# DSPIC33FJ128MC710A register map
Vendor: Microchip
Registers are 16-bit, read-write, reset 0x0 unless marked. A register's access mark holds for its fields unless they carry their own. Addresses are absolute, and some are shared; only a register's first bit layout is shown; [hi:lo] are bit positions; {n}, {i} and the like mark numbered series; 'fields as' and 'values as' point back to an identical list.

## SFR
{0x0+2i} WREG{i} (i=0..14)
0x1E WREG15 reset 0x800
0x20 SPLIM
0x22 ACCAL reset not defined — (power-on value xxxxxxxxxxxxxxxx)
0x24 ACCAH reset not defined — (power-on value xxxxxxxxxxxxxxxx)
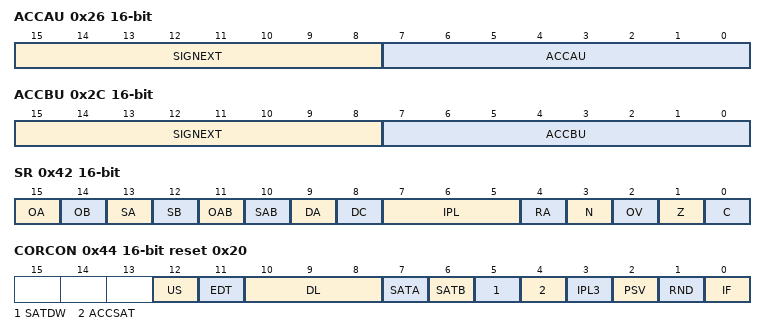
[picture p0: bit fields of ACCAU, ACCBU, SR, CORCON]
0x26 ACCAU reset not defined — (power-on value 00000000xxxxxxxx)
  [15:8] SIGNEXT ro, [7:0] ACCAU
0x28 ACCBL reset not defined — (power-on value xxxxxxxxxxxxxxxx)
0x2A ACCBH reset not defined — (power-on value xxxxxxxxxxxxxxxx)
0x2C ACCBU reset not defined — (power-on value 00000000xxxxxxxx)
  [15:8] SIGNEXT ro, [7:0] ACCBU
0x2E PCL ro
0x30 PCH ro
  [7:0] PCH
0x32 TBLPAG
  [7:0] TBLPAG
0x34 PSVPAG
  [7:0] PSVPAG
0x36 RCOUNT reset not defined — (power-on value --xxxxxxxxxxxxxx)
  [13:0] RCOUNT
0x38 DCOUNT reset not defined — (power-on value --xxxxxxxxxxxxxx)
  [13:0] DCOUNT
0x3A DOSTARTL reset not defined — (power-on value xxxxxxxxxxxxxxx0)
0x3C DOSTARTH reset not defined — (power-on value ----------xxxxxx)
  [5:0] DOSTARTH
0x3E DOENDL reset not defined — (power-on value xxxxxxxxxxxxxxx0)
0x40 DOENDH reset not defined — (power-on value ----------xxxxxx)
  [5:0] DOENDH
0x42 SR
  [15] OA ro
  [14] OB ro
  [13] SA — (can only be cleared)
  [12] SB — (can only be cleared)
  [11] OAB ro
  [10] SAB — (can only be cleared)
  [9] DA ro
  [8] DC
  [7:5] IPL
  [4] RA ro
  [3] N
  [2] OV
  [1] Z
  [0] C
0x44 CORCON reset 0x20
  [12] US
  [11] EDT wo
  [10:8] DL ro
  [7] SATA
  [6] SATB
  [5] SATDW
  [4] ACCSAT
  [3] IPL3 — (can only be cleared)
  [2] PSV
  [1] RND
  [0] IF
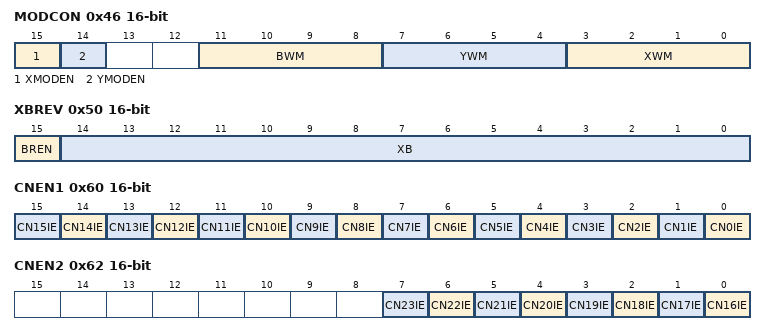
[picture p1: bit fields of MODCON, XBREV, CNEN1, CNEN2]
0x46 MODCON
  [15] XMODEN, [14] YMODEN, [11:8] BWM, [7:4] YWM, [3:0] XWM
0x48 XMODSRT reset not defined — (power-on value xxxxxxxxxxxxxxx0)
  [15:0] XS
0x4A XMODEND reset not defined — (power-on value xxxxxxxxxxxxxxx1)
  [15:0] XE
0x4C YMODSRT reset not defined — (power-on value xxxxxxxxxxxxxxx0)
  [15:0] YS
0x4E YMODEND reset not defined — (power-on value xxxxxxxxxxxxxxx1)
  [15:0] YE
0x50 XBREV reset not defined — (power-on value 0xxxxxxxxxxxxxxx)
  [15] BREN, [14:0] XB
0x52 DISICNT reset not defined — (power-on value --xxxxxxxxxxxxxx)
  [13:0] DISICNT
0x60 CNEN1
  [n] CN{n}IE (n=0..15)
0x62 CNEN2
  [n-16] CN{n}IE (n=16..23)
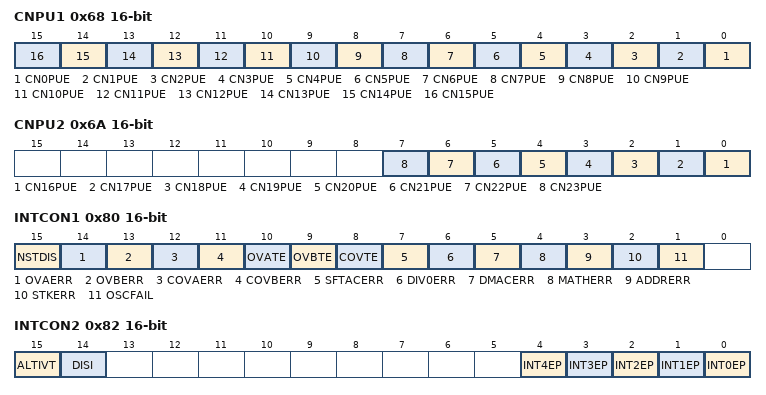
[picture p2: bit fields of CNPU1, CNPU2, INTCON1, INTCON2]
0x68 CNPU1
  [n] CN{n}PUE (n=0..15)
0x6A CNPU2
  [n-16] CN{n}PUE (n=16..23)
0x80 INTCON1
  [15] NSTDIS, [14] OVAERR ro, [13] OVBERR ro, [12] COVAERR ro, [11] COVBERR ro, [10] OVATE, [9] OVBTE, [8] COVTE, [7] SFTACERR ro, [6] DIV0ERR ro, [5] DMACERR, [4] MATHERR, [3] ADDRERR, [2] STKERR, [1] OSCFAIL
0x82 INTCON2
  [15] ALTIVT, [14] DISI ro, [n] INT{n}EP (n=0..4)
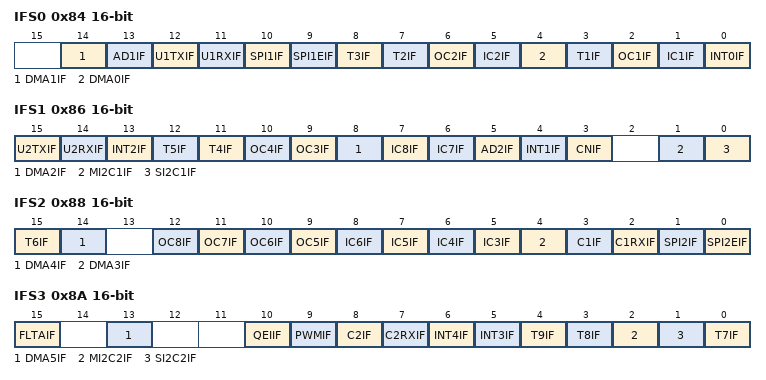
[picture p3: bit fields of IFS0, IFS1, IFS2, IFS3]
0x84 IFS0
  [14] DMA1IF, [13] AD1IF, [12] U1TXIF, [11] U1RXIF, [10] SPI1IF, [9] SPI1EIF, [8] T3IF, [7] T2IF, [6] OC2IF, [5] IC2IF, [4] DMA0IF, [3] T1IF, [2] OC1IF, [1] IC1IF, [0] INT0IF
0x86 IFS1
  [15] U2TXIF, [14] U2RXIF, [13] INT2IF, [12] T5IF, [11] T4IF, [10] OC4IF, [9] OC3IF, [8] DMA2IF, [7] IC8IF, [6] IC7IF, [5] AD2IF, [4] INT1IF, [3] CNIF, [1] MI2C1IF, [0] SI2C1IF
0x88 IFS2
  [15] T6IF, [14] DMA4IF, [n+4] OC{n}IF (n=5..8), [n+2] IC{n}IF (n=3..6), [4] DMA3IF, [3] C1IF, [2] C1RXIF, [1] SPI2IF, [0] SPI2EIF
0x8A IFS3
  [15] FLTAIF, [13] DMA5IF, [10] QEIIF, [9] PWMIF, [8] C2IF, [7] C2RXIF, [6] INT4IF, [5] INT3IF, [4] T9IF, [3] T8IF, [2] MI2C2IF, [1] SI2C2IF, [0] T7IF
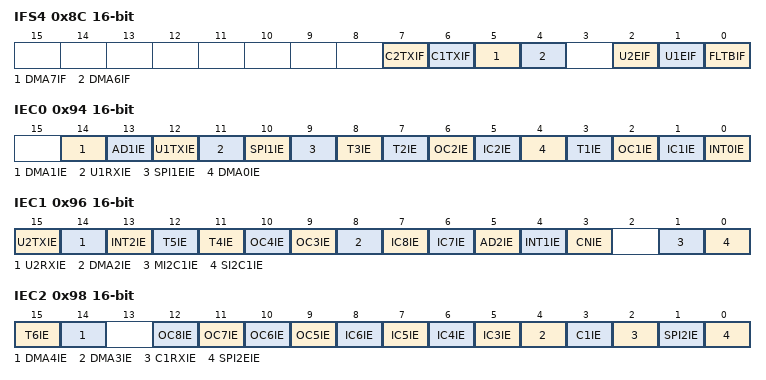
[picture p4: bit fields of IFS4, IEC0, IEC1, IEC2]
0x8C IFS4
  [7] C2TXIF, [6] C1TXIF, [5] DMA7IF, [4] DMA6IF, [2] U2EIF, [1] U1EIF, [0] FLTBIF
0x94 IEC0
  [14] DMA1IE, [13] AD1IE, [12] U1TXIE, [11] U1RXIE, [10] SPI1IE, [9] SPI1EIE, [8] T3IE, [7] T2IE, [6] OC2IE, [5] IC2IE, [4] DMA0IE, [3] T1IE, [2] OC1IE, [1] IC1IE, [0] INT0IE
0x96 IEC1
  [15] U2TXIE, [14] U2RXIE, [13] INT2IE, [12] T5IE, [11] T4IE, [10] OC4IE, [9] OC3IE, [8] DMA2IE, [7] IC8IE, [6] IC7IE, [5] AD2IE, [4] INT1IE, [3] CNIE, [1] MI2C1IE, [0] SI2C1IE
0x98 IEC2
  [15] T6IE, [14] DMA4IE, [n+4] OC{n}IE (n=5..8), [n+2] IC{n}IE (n=3..6), [4] DMA3IE, [3] C1IE, [2] C1RXIE, [1] SPI2IE, [0] SPI2EIE
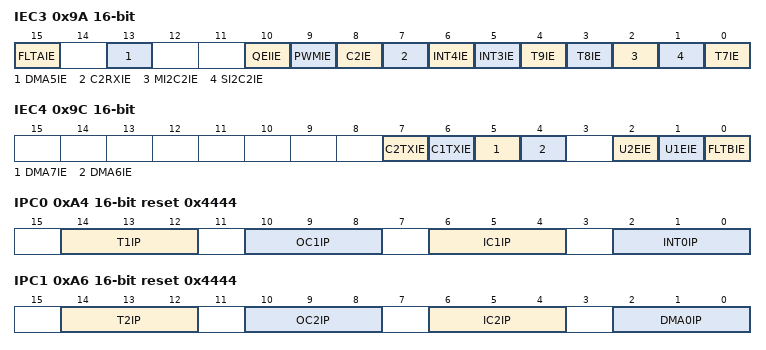
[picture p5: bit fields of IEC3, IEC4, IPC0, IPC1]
0x9A IEC3
  [15] FLTAIE, [13] DMA5IE, [10] QEIIE, [9] PWMIE, [8] C2IE, [7] C2RXIE, [6] INT4IE, [5] INT3IE, [4] T9IE, [3] T8IE, [2] MI2C2IE, [1] SI2C2IE, [0] T7IE
0x9C IEC4
  [7] C2TXIE, [6] C1TXIE, [5] DMA7IE, [4] DMA6IE, [2] U2EIE, [1] U1EIE, [0] FLTBIE
0xA4 IPC0 reset 0x4444
  [14:12] T1IP, [10:8] OC1IP, [6:4] IC1IP, [2:0] INT0IP
0xA6 IPC1 reset 0x4444
  [14:12] T2IP, [10:8] OC2IP, [6:4] IC2IP, [2:0] DMA0IP
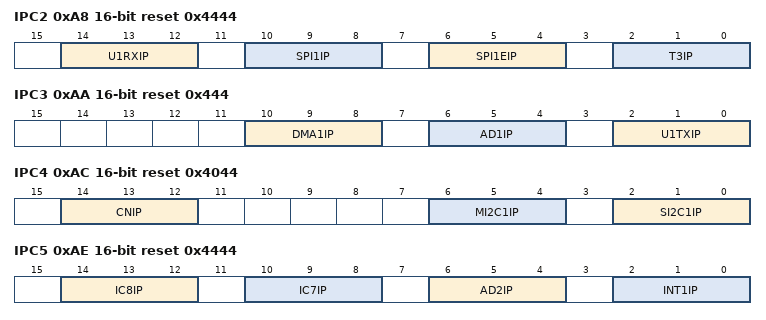
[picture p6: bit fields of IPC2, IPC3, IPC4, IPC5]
0xA8 IPC2 reset 0x4444
  [14:12] U1RXIP, [10:8] SPI1IP, [6:4] SPI1EIP, [2:0] T3IP
0xAA IPC3 reset 0x444
  [10:8] DMA1IP, [6:4] AD1IP, [2:0] U1TXIP
0xAC IPC4 reset 0x4044
  [14:12] CNIP, [6:4] MI2C1IP, [2:0] SI2C1IP
0xAE IPC5 reset 0x4444
  [14:12] IC8IP, [10:8] IC7IP, [6:4] AD2IP, [2:0] INT1IP
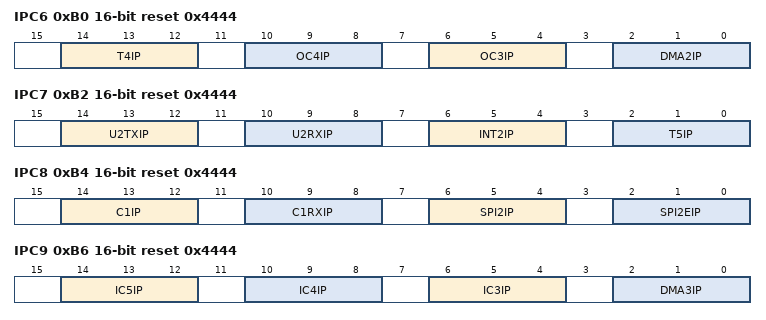
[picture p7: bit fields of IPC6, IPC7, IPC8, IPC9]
0xB0 IPC6 reset 0x4444
  [14:12] T4IP, [10:8] OC4IP, [6:4] OC3IP, [2:0] DMA2IP
0xB2 IPC7 reset 0x4444
  [14:12] U2TXIP, [10:8] U2RXIP, [6:4] INT2IP, [2:0] T5IP
0xB4 IPC8 reset 0x4444
  [14:12] C1IP, [10:8] C1RXIP, [6:4] SPI2IP, [2:0] SPI2EIP
0xB6 IPC9 reset 0x4444
  [14:12] IC5IP, [10:8] IC4IP, [6:4] IC3IP, [2:0] DMA3IP
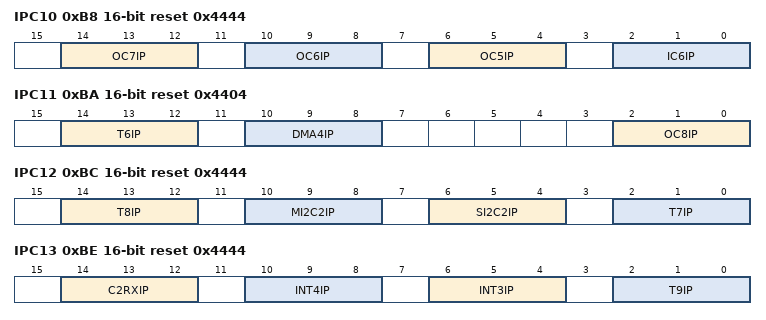
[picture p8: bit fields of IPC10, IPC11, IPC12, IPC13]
0xB8 IPC10 reset 0x4444
  [14:12] OC7IP, [10:8] OC6IP, [6:4] OC5IP, [2:0] IC6IP
0xBA IPC11 reset 0x4404
  [14:12] T6IP, [10:8] DMA4IP, [2:0] OC8IP
0xBC IPC12 reset 0x4444
  [14:12] T8IP, [10:8] MI2C2IP, [6:4] SI2C2IP, [2:0] T7IP
0xBE IPC13 reset 0x4444
  [14:12] C2RXIP, [10:8] INT4IP, [6:4] INT3IP, [2:0] T9IP
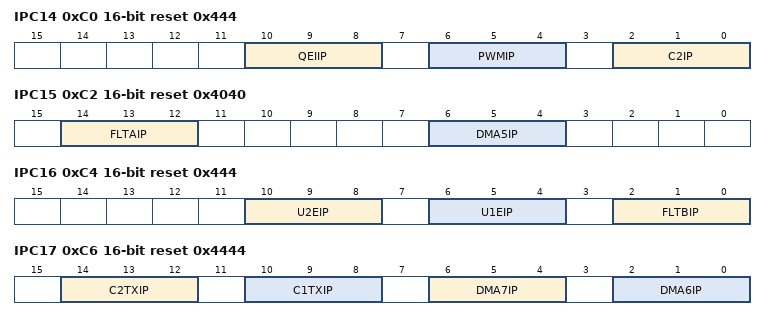
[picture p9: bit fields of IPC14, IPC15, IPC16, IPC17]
0xC0 IPC14 reset 0x444
  [10:8] QEIIP, [6:4] PWMIP, [2:0] C2IP
0xC2 IPC15 reset 0x4040
  [14:12] FLTAIP, [6:4] DMA5IP
0xC4 IPC16 reset 0x444
  [10:8] U2EIP, [6:4] U1EIP, [2:0] FLTBIP
0xC6 IPC17 reset 0x4444
  [14:12] C2TXIP, [10:8] C1TXIP, [6:4] DMA7IP, [2:0] DMA6IP
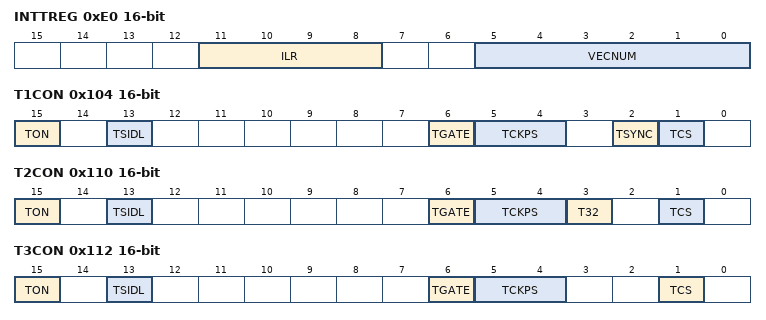
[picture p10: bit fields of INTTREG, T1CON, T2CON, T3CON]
0xE0 INTTREG ro
  [11:8] ILR, [5:0] VECNUM
0x100 TMR1 reset not defined — (power-on value xxxxxxxxxxxxxxxx)
0x102 PR1 reset 0xFFFF
0x104 T1CON
  [15] TON, [13] TSIDL, [6] TGATE, [5:4] TCKPS, [2] TSYNC, [1] TCS
0x106 TMR2 reset not defined — (power-on value xxxxxxxxxxxxxxxx)
0x108 TMR3HLD reset not defined — (power-on value xxxxxxxxxxxxxxxx)
0x10A TMR3 reset not defined — (power-on value xxxxxxxxxxxxxxxx)
0x10C PR2 reset 0xFFFF
0x10E PR3 reset 0xFFFF
0x110 T2CON
  [15] TON, [13] TSIDL, [6] TGATE, [5:4] TCKPS, [3] T32, [1] TCS
0x112 T3CON
  [15] TON, [13] TSIDL, [6] TGATE, [5:4] TCKPS, [1] TCS
0x114 TMR4 reset not defined — (power-on value xxxxxxxxxxxxxxxx)
0x116 TMR5HLD reset not defined — (power-on value xxxxxxxxxxxxxxxx)
0x118 TMR5 reset not defined — (power-on value xxxxxxxxxxxxxxxx)
0x11A PR4 reset 0xFFFF
0x11C PR5 reset 0xFFFF
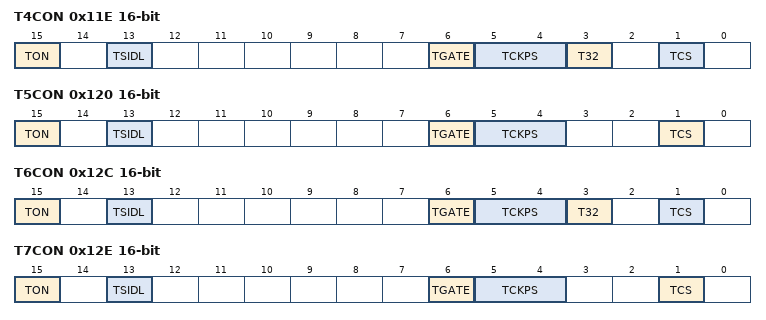
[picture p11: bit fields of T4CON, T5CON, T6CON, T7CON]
0x11E T4CON
  [15] TON, [13] TSIDL, [6] TGATE, [5:4] TCKPS, [3] T32, [1] TCS
0x120 T5CON
  [15] TON, [13] TSIDL, [6] TGATE, [5:4] TCKPS, [1] TCS
0x122 TMR6 reset not defined — (power-on value xxxxxxxxxxxxxxxx)
0x124 TMR7HLD reset not defined — (power-on value xxxxxxxxxxxxxxxx)
0x126 TMR7 reset not defined — (power-on value xxxxxxxxxxxxxxxx)
0x128 PR6 reset 0xFFFF
0x12A PR7 reset 0xFFFF
0x12C T6CON
  [15] TON, [13] TSIDL, [6] TGATE, [5:4] TCKPS, [3] T32, [1] TCS
0x12E T7CON
  [15] TON, [13] TSIDL, [6] TGATE, [5:4] TCKPS, [1] TCS
0x130 TMR8 reset not defined — (power-on value xxxxxxxxxxxxxxxx)
0x132 TMR9HLD reset not defined — (power-on value xxxxxxxxxxxxxxxx)
0x134 TMR9 reset not defined — (power-on value xxxxxxxxxxxxxxxx)
0x136 PR8 reset 0xFFFF
0x138 PR9 reset 0xFFFF
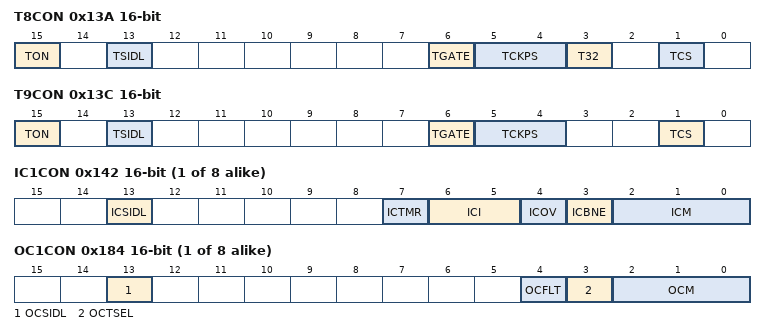
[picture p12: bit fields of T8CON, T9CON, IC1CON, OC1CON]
0x13A T8CON
  [15] TON, [13] TSIDL, [6] TGATE, [5:4] TCKPS, [3] T32, [1] TCS
0x13C T9CON
  [15] TON, [13] TSIDL, [6] TGATE, [5:4] TCKPS, [1] TCS
{0x13C+4i} IC{i}BUF ro reset not defined (i=1..8) — (power-on value xxxxxxxxxxxxxxxx)
{0x13E+4i} IC{i}CON (i=1..8)
  [13] ICSIDL, [7] ICTMR, [6:5] ICI, [4] ICOV ro, [3] ICBNE ro, [2:0] ICM
{0x17A+6i} OC{i}RS reset not defined (i=1..5) — (power-on value xxxxxxxxxxxxxxxx)
{0x17C+6i} OC{i}R reset not defined (i=1..5) — (power-on value xxxxxxxxxxxxxxxx)
{0x17E+6i} OC{i}CON (i=1..8)
  [13] OCSIDL, [4] OCFLT ro, [3] OCTSEL, [2:0] OCM
{0x17A+6i} OC{i}RS (i=6..8)
{0x17C+6i} OC{i}R (i=6..8)
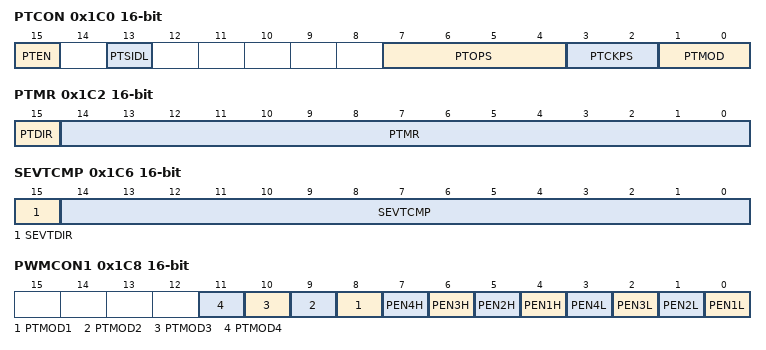
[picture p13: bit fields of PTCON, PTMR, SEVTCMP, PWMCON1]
0x1C0 PTCON
  [15] PTEN, [13] PTSIDL, [7:4] PTOPS, [3:2] PTCKPS, [1:0] PTMOD
0x1C2 PTMR
  [15] PTDIR ro, [14:0] PTMR
0x1C4 PTPER reset 0x7FFF
  [14:0] PTPER
0x1C6 SEVTCMP
  [15] SEVTDIR, [14:0] SEVTCMP
0x1C8 PWMCON1 reset not defined — (power-on value ----0000qqqqqqqq)
  [n+7] PTMOD{n} (n=1..4), [n+3] PEN{n}H (n=1..4), [n-1] PEN{n}L (n=1..4)
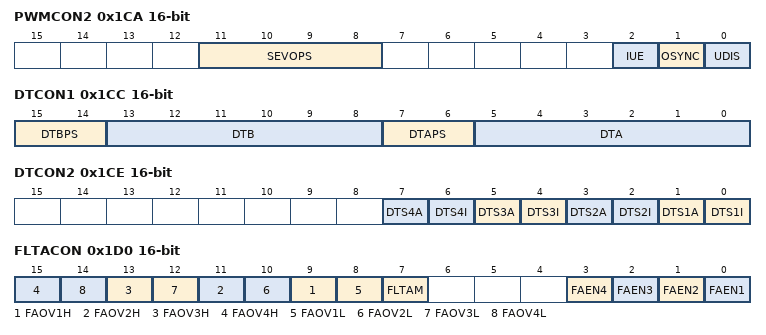
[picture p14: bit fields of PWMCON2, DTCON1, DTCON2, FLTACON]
0x1CA PWMCON2
  [11:8] SEVOPS, [2] IUE, [1] OSYNC, [0] UDIS
0x1CC DTCON1
  [15:14] DTBPS, [13:8] DTB, [7:6] DTAPS, [5:0] DTA
0x1CE DTCON2
  [2n-1] DTS{n}A (n=1..4), [2n-2] DTS{n}I (n=1..4)
0x1D0 FLTACON
  [2n+7] FAOV{n}H (n=1..4), [2n+6] FAOV{n}L (n=1..4), [7] FLTAM, [n-1] FAEN{n} (n=1..4)
0x1D2 FLTBCON
  [2n+7] FBOV{n}H (n=1..4), [2n+6] FBOV{n}L (n=1..4), [7] FLTBM, [n-1] FBEN{n} (n=1..4)
0x1D4 OVDCON reset 0xFF00
  [2n+7] POVD{n}H (n=1..4), [2n+6] POVD{n}L (n=1..4), [2n-1] POUT{n}H (n=1..4), [2n-2] POUT{n}L (n=1..4)
{0x1D4+2i} PDC{i} (i=1..4)
0x1E0 QEICON
  [15] CNTERR, [13] QEISIDL, [12] INDX ro, [11] UPDN, [10] QEIM2, [9] QEIM1, [8] QEIM0, [7] SWPAB, [6] PCDOUT, [5] TQGATE, [4] TQCKPS1, [3] TQCKPS0, [2] POSRES, [1] TQCS, [0] UPDN_SRC
0x1E2 DFLTCON
  [10] IMV1, [9] IMV0, [8] CEID, [7] QEOUT, [6] QECK2, [5] QECK1, [4] QECK0
0x1E4 POSCNT
0x1E6 MAXCNT reset 0xFFFF
0x200 I2C1RCV ro
  [7:0] I2C1RCV
0x202 I2C1TRN wo reset 0xFF
  [7:0] I2C1TRN
0x204 I2C1BRG
  [8:0] I2C1BRG
0x206 I2C1CON reset 0x1000
  [15] I2CEN, [13] I2CSIDL, [12] SCLREL, [11] IPMIEN, [10] A10M, [9] DISSLW, [8] SMEN, [7] GCEN, [6] STREN, [5] ACKDT, [4] ACKEN, [3] RCEN, [2] PEN, [1] RSEN, [0] SEN
0x208 I2C1STAT
  [15] ACKSTAT ro
  [14] TRSTAT ro
  [10] BCL — (can only be cleared)
  [9] GCSTAT ro
  [8] ADD10 ro
  [7] IWCOL — (can only be cleared)
  [6] I2COV — (can only be cleared)
  [5] D_A ro
  [4] P — (can only be cleared)
  [3] S — (can only be cleared)
  [2] R_W ro
  [1] RBF ro
  [0] TBF ro
0x20A I2C1ADD
  [9:0] I2C1ADD
0x20C I2C1MSK
  [9:0] AMSK
0x210 I2C2RCV ro
  [7:0] I2C2RCV
0x212 I2C2TRN wo reset 0xFF
  [7:0] I2C2TRN
0x214 I2C2BRG
  [8:0] I2C2BRG
0x216 I2C2CON reset 0x1000
  fields as I2C1CON
0x218 I2C2STAT
  fields as I2C1STAT
0x21A I2C2ADD
  [9:0] I2C2ADD
0x21C I2C2MSK
  [9:0] AMSK
0x220 U1MODE
  [15] UARTEN, [13] USIDL, [12] IREN, [11] RTSMD, [9:8] UEN, [7] WAKE, [6] LPBACK, [5] ABAUD, [4] URXINV, [3] BRGH, [2:1] PDSEL, [0] STSEL
0x222 U1STA reset 0x110
  [15] UTXISEL1
  [14] UTXINV
  [13] UTXISEL0
  [11] UTXBRK
  [10] UTXEN
  [9] UTXBF ro
  [8] TRMT ro
  [7:6] URXISEL
  [5] ADDEN
  [4] RIDLE ro
  [3] PERR ro
  [2] FERR ro
  [1] OERR — (can only be cleared)
  [0] URXDA ro
0x224 U1TXREG wo reset not defined — (power-on value -------xxxxxxxxx)
  [8:0] U1TXREG
0x226 U1RXREG ro
  [8:0] U1RXREG
0x228 U1BRG
  [15:0] BRG
0x230 U2MODE
  fields as U1MODE
0x232 U2STA reset 0x110
  fields as U1STA
0x234 U2TXREG wo reset not defined — (power-on value -------xxxxxxxxx)
  [8:0] U2TXREG
0x236 U2RXREG ro
  [8:0] U2RXREG
0x238 U2BRG
  [15:0] BRG
0x240 SPI1STAT
  [15] SPIEN
  [13] SPISIDL
  [6] SPIROV — (can only be cleared)
  [1] SPITBF
  [0] SPIRBF
0x242 SPI1CON1
  [12] DISSCK, [11] DISSDO, [10] MODE16, [9] SMP, [8] CKE, [7] SSEN, [6] CKP, [5] MSTEN, [4:2] SPRE, [1:0] PPRE
0x244 SPI1CON2
  [15] FRMEN, [14] SPIFSD, [13] FRMPOL, [1] FRMDLY
0x248 SPI1BUF
0x260 SPI2STAT
  fields as SPI1STAT
0x262 SPI2CON1
  fields as SPI1CON1
0x264 SPI2CON2
  [15] FRMEN, [14] SPIFSD, [13] FRMPOL, [1] FRMDLY
0x268 SPI2BUF
0x2C0 TRISA reset 0xC6FF
  [15] TRISA15, [14] TRISA14, [10] TRISA10, [9] TRISA9, [n] TRISA{n} (n=0..7)
0x2C2 PORTA reset not defined — (power-on value xx---xx-xxxxxxxx)
  [15] RA15, [14] RA14, [10] RA10, [9] RA9, [n] RA{n} (n=0..7)
0x2C4 LATA
  [15] LATA15, [14] LATA14, [10] LATA10, [9] LATA9, [n] LATA{n} (n=0..7)
0x2C6 TRISB reset 0xFFFF
  [n] TRISB{n} (n=0..15)
0x2C8 PORTB reset not defined — (power-on value xxxxxxxxxxxxxxxx)
  [n] RB{n} (n=0..15)
0x2CA LATB
  [n] LATB{n} (n=0..15)
0x2CC TRISC reset 0xF01E
  [n] TRISC{n} (n=12..15), [n] TRISC{n} (n=1..4)
0x2CE PORTC reset not defined — (power-on value xxxx-------xxxx-)
  [n] RC{n} (n=12..15), [n] RC{n} (n=1..4)
0x2D0 LATC
  [n] LATC{n} (n=12..15), [n] LATC{n} (n=1..4)
0x2D2 TRISD reset 0xFFFF
  [n] TRISD{n} (n=0..15)
0x2D4 PORTD reset not defined — (power-on value xxxxxxxxxxxxxxxx)
  [n] RD{n} (n=0..15)
0x2D6 LATD
  [n] LATD{n} (n=0..15)
0x2D8 TRISE reset 0x3FF
  [n] TRISE{n} (n=0..9)
0x2DA PORTE reset not defined — (power-on value ------xxxxxxxxxx)
  [n] RE{n} (n=0..9)
0x2DC LATE
  [n] LATE{n} (n=0..9)
0x2DE TRISF reset 0x31FF
  [13] TRISF13, [12] TRISF12, [n] TRISF{n} (n=0..8)
0x2E0 PORTF reset not defined — (power-on value --xx---xxxxxxxxx)
  [13] RF13, [12] RF12, [n] RF{n} (n=0..8)
0x2E2 LATF
  [13] LATF13, [12] LATF12, [n] LATF{n} (n=0..8)
0x2E4 TRISG reset 0xF3CF
  [n] TRISG{n} (n=12..15), [n] TRISG{n} (n=6..9), [n] TRISG{n} (n=0..3)
0x2E6 PORTG reset not defined — (power-on value xxxx--xxxx--xxxx)
  [n] RG{n} (n=12..15), [n] RG{n} (n=6..9), [n] RG{n} (n=0..3)
0x2E8 LATG
  [n] LATG{n} (n=12..15), [n] LATG{n} (n=6..9), [n] LATG{n} (n=0..3)
0x300 ADC1BUF0 ro reset not defined — (power-on value xxxxxxxxxxxxxxxx)
  [11:0] ADCBUF0
0x320 AD1CON1
  [15] ADON
  [13] ADSIDL
  [12] ADDMABM
  [10] AD12B
  [9:8] FORM
  [7:5] SSRC
  [3] SIMSAM
  [2] ASAM
  [1] SAMP
  [0] DONE — (can only be cleared)
0x322 AD1CON2
  [15:13] VCFG, [10] CSCNA, [9:8] CHPS, [7] BUFS ro, [5:2] SMPI, [1] BUFM, [0] ALTS
0x324 AD1CON3
  [15] ADRC, [12:8] SAMC, [5:0] ADCS
0x326 AD1CHS123
  [10:9] CH123NB, [8] CH123SB, [2:1] CH123NA, [0] CH123SA
0x328 AD1CHS0
  [15] CH0NB, [12:8] CH0SB, [7] CH0NA, [4:0] CH0SA
0x32A AD1PCFGH
  [15:0] PCFG
0x32C AD1PCFGL
  [15:0] PCFG
0x32E AD1CSSH
  [15:0] CSSH
0x330 AD1CSSL
  [15:0] CSSL
0x332 AD1CON4
  [2:0] DMABL
0x340 ADC2BUF0 ro reset not defined — (power-on value xxxxxxxxxxxxxxxx)
  [11:0] ADCBUF0
0x360 AD2CON1
  fields as AD1CON1
0x362 AD2CON2
  fields as AD1CON2
0x364 AD2CON3
  [15] ADRC, [12:8] SAMC, [5:0] ADCS
0x366 AD2CHS123
  [10:9] CH123NB, [8] CH123SB, [2:1] CH123NA, [0] CH123SA
0x368 AD2CHS0
  [15] CH0NB, [11:8] CH0SB, [7] CH0NA, [3:0] CH0SA
0x36C AD2PCFGL
  [15:0] PCFG
0x370 AD2CSSL
  [15:0] CSSL
0x372 AD2CON4
  [2:0] DMABL
{0x380+0xC*i} DMA{i}CON (i=0..7)
  [15] CHEN, [14] SIZE, [13] DIR, [12] HALF, [11] NULLW, [5:4] AMODE, [1:0] MODE
{0x382+0xC*i} DMA{i}REQ (i=0..7)
  [15] FORCE — (can only be set)
  [6:0] IRQSEL
{0x384+0xC*i} DMA{i}STA (i=0..7)
  [15:0] STA
{0x386+0xC*i} DMA{i}STB (i=0..7)
  [15:0] STB
{0x388+0xC*i} DMA{i}PAD (i=0..7)
  [15:0] PAD
{0x38A+0xC*i} DMA{i}CNT (i=0..7)
  [15:0] CNT
0x3E0 DMACS0 ro
  [n+8] PWCOL{n} (n=0..7), [n] XWCOL{n} (n=0..7)
0x3E2 DMACS1 ro reset 0xF00
  [11:8] LSTCH, [n] PPST{n} (n=0..7)
0x3E4 DSADR ro
0x400 C1CTRL1 reset 0x480
  [13] CSIDL, [12] ABAT, [11] CANCKS, [10:8] REQOP, [7:5] OPMODE ro, [3] CANCAP, [0] WIN
0x402 C1CTRL2 ro
  [4:0] DNCNT
0x404 C1VEC ro reset 0x40
  [12:8] FILHIT, [6:0] ICODE
0x406 C1FCTRL
  [15:13] DMABS, [4:0] FSA
0x408 C1FIFO ro
  [13:8] FBP, [5:0] FNRB
0x40A C1INTF
  [13] TXBO ro
  [12] TXBP ro
  [11] RXBP ro
  [10] TXWAR ro
  [9] RXWAR ro
  [8] EWARN ro
  [7] IVRIF — (can only be cleared)
  [6] WAKIF — (can only be cleared)
  [5] ERRIF — (can only be cleared)
  [3] FIFOIF — (can only be cleared)
  [2] RBOVIF — (can only be cleared)
  [1] RBIF — (can only be cleared)
  [0] TBIF — (can only be cleared)
0x40C C1INTE
  [7] IVRIE, [6] WAKIE, [5] ERRIE, [3] FIFOIE, [2] RBOVIE, [1] RBIE, [0] TBIE
0x40E C1EC
  [15:8] TERRCNT, [7:0] RERRCNT
0x410 C1CFG1
  [7:6] SJW, [5:0] BRP
0x412 C1CFG2 reset not defined — (power-on value -x---xxxxxxxxxxx)
  [14] WAKFIL, [10:8] SEG2PH, [7] SEG2PHTS, [6] SAM, [5:3] SEG1PH, [2:0] PRSEG
0x414 C1FEN1 reset 0x3F
  [n] FLTEN{n} (n=0..15)
0x418 C1FMSKSEL1
  [2n+1:2n] F{n}MSK (n=0..7)
0x41A C1FMSKSEL2
  [2n-15:2n-16] F{n}MSK (n=8..15)
0x420 C1RXFUL1
  [n] RXFUL{n} (n=0..15) — (can only be cleared)
0x420 C1BUFPNT1
  [4n+3:4n] F{n}BP (n=0..3)
0x422 C1RXFUL2
  [n-16] RXFUL{n} (n=16..31) — (can only be cleared)
0x422 C1BUFPNT2
  [4n-13:4n-16] F{n}BP (n=4..7)
0x424 C1BUFPNT3
  [4n-29:4n-32] F{n}BP (n=8..11)
0x426 C1BUFPNT4
  [4n-45:4n-48] F{n}BP (n=12..15)
0x428 C1RXOVF1
  [n] RXOVF{n} (n=0..15) — (can only be cleared)
0x42A C1RXOVF2
  [n-16] RXOVF{n} (n=16..31) — (can only be cleared)
0x430 C1TR01CON
  [15] TXEN1, [14] TXABT1 ro, [13] TXLARB1 ro, [12] TXERR1 ro, [11] TXREQ1, [10] RTREN1, [9:8] TX1PRI, [7] TXEN0, [6] TXABT0 ro, [5] TXLARB0 ro, [4] TXERR0 ro, [3] TXREQ0, [2] RTREN0, [1:0] TX0PRI
{0x430+4i} C1RXM{i}SID reset not defined (i=0..2) — (power-on value xxxxxxxxxxx-x-xx)
  [n+5] SID{n} (n=0..10), [3] MIDE, [1] EID17, [0] EID16
0x432 C1TR23CON
  [15] TXEN3, [14] TXABT3 ro, [13] TXLARB3 ro, [12] TXERR3 ro, [11] TXREQ3, [10] RTREN3, [9:8] TX3PRI, [7] TXEN2, [6] TXABT2 ro, [5] TXLARB2 ro, [4] TXERR2 ro, [3] TXREQ2, [2] RTREN2, [1:0] TX2PRI
{0x432+4i} C1RXM{i}EID reset not defined (i=0..2) — (power-on value xxxxxxxxxxxxxxxx)
  [n] EID{n} (n=0..15)
0x434 C1TR45CON
  [15] TXEN5, [14] TXABT5 ro, [13] TXLARB5 ro, [12] TXERR5 ro, [11] TXREQ5, [10] RTREN5, [9:8] TX5PRI, [7] TXEN4, [6] TXABT4 ro, [5] TXLARB4 ro, [4] TXERR4 ro, [3] TXREQ4, [2] RTREN4, [1:0] TX4PRI
0x436 C1TR67CON
  [15] TXEN7, [14] TXABT7 ro, [13] TXLARB7 ro, [12] TXERR7 ro, [11] TXREQ7, [10] RTREN7, [9:8] TX7PRI, [7] TXEN6, [6] TXABT6 ro, [5] TXLARB6 ro, [4] TXERR6 ro, [3] TXREQ6, [2] RTREN6, [1:0] TX6PRI
0x440 C1RXD reset not defined — (power-on value xxxxxxxxxxxxxxxx)
{0x440+4i} C1RXF{i}SID reset not defined (i=0..15) — (power-on value xxxxxxxxxxx-x-xx)
  [n+5] SID{n} (n=0..10), [3] EXIDE, [1] EID17, [0] EID16
0x442 C1TXD reset not defined — (power-on value xxxxxxxxxxxxxxx-)
  [15:1] C1TXD
{0x442+4i} C1RXF{i}EID reset not defined (i=0..15) — (power-on value xxxxxxxxxxxxxxxx)
  [n] EID{n} (n=0..15)
0x500 C2CTRL1 reset 0x480
  fields as C1CTRL1
0x502 C2CTRL2 ro
  [4:0] DNCNT
0x504 C2VEC ro reset 0x40
  [12:8] FILHIT, [6:0] ICODE
0x506 C2FCTRL
  [15:13] DMABS, [4:0] FSA
0x508 C2FIFO ro
  [13:8] FBP, [5:0] FNRB
0x50A C2INTF
  [13] TXBO ro
  [12] TXBP ro
  [11] RXBP ro
  [10] TXWARN ro
  [9] RXWARN ro
  [8] EWARN ro
  [7] IVRIF — (can only be cleared)
  [6] WAKIF — (can only be cleared)
  [5] ERRIF — (can only be cleared)
  [3] FIFOIF — (can only be cleared)
  [2] RBOVIF — (can only be cleared)
  [1] RBIF — (can only be cleared)
  [0] TBIF — (can only be cleared)
0x50C C2INTE
  fields as C1INTE
0x50E C2EC
  [15:8] TERRCNT, [7:0] RERRCNT
0x510 C2CFG1
  [7:6] SJW, [5:0] BRP
0x512 C2CFG2 reset not defined — (power-on value 0x000xxxxxxxxxxx)
  fields as C1CFG2
0x514 C2FEN1 reset 0x3F
  [n] FLTEN{n} (n=0..15)
0x518 C2FMSKSEL1
  [2n+1:2n] F{n}MSK (n=0..7)
0x51A C2FMSKSEL2
  [2n-15:2n-16] F{n}MSK (n=8..15)
0x520 C2RXFUL1
  [n] RXFUL{n} (n=0..15) — (can only be cleared)
0x520 C2BUFPNT1
  [4n+3:4n] F{n}BP (n=0..3)
0x522 C2RXFUL2
  [n-16] RXFUL{n} (n=16..31) — (can only be cleared)
0x522 C2BUFPNT2
  [4n-13:4n-16] F{n}BP (n=4..7)
0x524 C2BUFPNT3
  [4n-29:4n-32] F{n}BP (n=8..11)
0x526 C2BUFPNT4
  [4n-45:4n-48] F{n}BP (n=12..15)
0x528 C2RXOVF1
  [n] RXOVF{n} (n=0..15) — (can only be cleared)
0x52A C2RXOVF2
  [n-16] RXOVF{n} (n=16..31) — (can only be cleared)
0x530 C2TR01CON
  fields as C1TR01CON
{0x530+4i} C2RXM{i}SID (i=0..2)
  [n+5] SID{n} (n=0..10), [3] MIDE, [1] EID17, [0] EID16
0x532 C2TR23CON
  fields as C1TR23CON
{0x532+4i} C2RXM{i}EID (i=0..2)
  [n] EID{n} (n=0..15)
0x534 C2TR45CON
  fields as C1TR45CON
0x536 C2TR67CON
  fields as C1TR67CON
0x540 C2RXD
{0x540+4i} C2RXF{i}SID (i=0..15)
  [n+5] SID{n} (n=0..10), [3] EXIDE, [1] EID17, [0] EID16
0x542 C2TXD
{0x542+4i} C2RXF{i}EID (i=0..15)
  [n] EID{n} (n=0..15)
0x6C0 ODCA
  [15] ODCA15, [14] ODCA14, [n] ODCA{n} (n=0..5)
0x6D2 ODCD
  [n] ODCD{n} (n=0..15)
0x6DE ODCF
  [13] ODCF13, [12] ODCF12, [n] ODCF{n} (n=0..8)
0x6E4 ODCG
  [n] ODCG{n} (n=12..15), [n] ODCG{n} (n=6..9), [n] ODCG{n} (n=0..3)
0x740 RCON reset 0x3
  [15] TRAPR, [14] IOPUWR, [8] VREGS, [7] EXTR, [6] SWR, [5] SWDTEN, [4] WDTO, [3] SLEEP, [2] IDLE, [1] BOR, [0] POR
0x742 OSCCON reset not defined — (power-on value -000-yyy0---0000)
  [14:12] COSC ro, [10:8] NOSC, [7] CLKLOCK, [5] LOCK ro, [3] CF ro, [1] LPOSCEN, [0] OSWEN
0x744 CLKDIV reset 0x3040
  [15] ROI, [14:12] DOZE, [11] DOZEN, [10:8] FRCDIV, [7:6] PLLPOST, [4:0] PLLPRE
0x746 PLLFBD reset 0x30
  [8:0] PLLDIV
0x748 OSCTUN
  [5:0] TUN
0x750 BSRAM reset not defined — (power-on value -------------xxx)
  [2] IW_BSR, [1] IR_BSR, [0] RL_BSR
0x752 SSRAM reset not defined — (power-on value -------------xxx)
  [2] IW_SSR, [1] IR_SSR, [0] RL_SSR
0x760 NVMCON
  [15] WR — (can only be set)
  [14] WREN
  [13] WRERR
  [6] ERASE
  [3:0] NVMOP
0x766 NVMKEY wo
  [7:0] NVMKEY
0x770 PMD1
  [n+10] T{n}MD (n=1..5), [10] QEIMD, [9] PWMMD, [7] I2C1MD, [6] U2MD, [5] U1MD, [4] SPI2MD, [3] SPI1MD, [2] C2MD, [1] C1MD, [0] AD1MD
0x772 PMD2
  [n+7] IC{n}MD (n=1..8), [n-1] OC{n}MD (n=1..8)
0x774 PMD3
  [n+6] T{n}MD (n=6..9), [1] I2C2MD, [0] AD2MD
